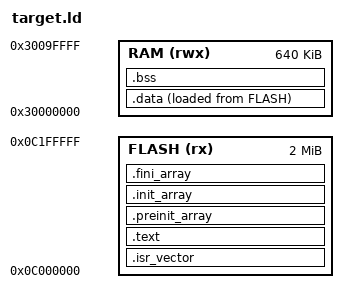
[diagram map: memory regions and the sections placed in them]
/* target.ld
 *
 * Copyright (C) 2026 wolfSSL Inc.
 *
 * This file is part of wolfNano.
 *
 * wolfNano is free software; you can redistribute it and/or modify
 * it under the terms of the GNU General Public License as published by
 * the Free Software Foundation; either version 3 of the License, or
 * (at your option) any later version.
 *
 * wolfNano is distributed in the hope that it will be useful,
 * but WITHOUT ANY WARRANTY; without even the implied warranty of
 * MERCHANTABILITY or FITNESS FOR A PARTICULAR PURPOSE.  See the
 * GNU General Public License for more details.
 *
 * You should have received a copy of the GNU General Public License
 * along with this program; if not, see <https://www.gnu.org/licenses/>.
 */

/* STM32H563 secure boot map (m33mu boots ARMv8-M secure at 0x0C000000). */
MEMORY
{
    FLASH (rx)  : ORIGIN = 0x0C000000, LENGTH = 0x00200000
    RAM   (rwx) : ORIGIN = 0x30000000, LENGTH = 0x000A0000
}

_estack = ORIGIN(RAM) + LENGTH(RAM);
_sidata = LOADADDR(.data);

SECTIONS
{
    .isr_vector :
    {
        KEEP(*(.isr_vector))
    } > FLASH

    .text :
    {
        *(.text*)
        *(.rodata*)
        *(.ARM.extab* .gnu.linkonce.armextab.*)
        *(.ARM.exidx* .gnu.linkonce.armexidx.*)
        *(.glue_7)
        *(.glue_7t)
        *(.eh_frame)
    } > FLASH

    .preinit_array :
    {
        __preinit_array_start = .;
        KEEP(*(.preinit_array*))
        __preinit_array_end = .;
    } > FLASH

    .init_array :
    {
        __init_array_start = .;
        KEEP(*(.init_array*))
        __init_array_end = .;
    } > FLASH

    .fini_array :
    {
        __fini_array_start = .;
        KEEP(*(.fini_array*))
        __fini_array_end = .;
    } > FLASH

    .data :
    {
        _sdata = .;
        *(.data*)
        _edata = .;
    } > RAM AT > FLASH

    .bss (NOLOAD) :
    {
        _sbss = .;
        *(.bss*)
        *(COMMON)
        _ebss = .;
    } > RAM
}
